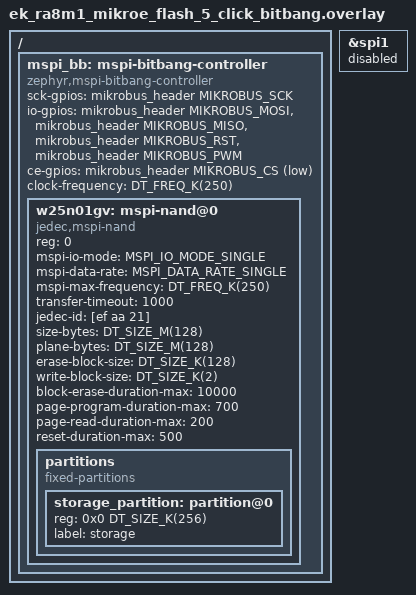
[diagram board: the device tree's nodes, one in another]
/*
 * Copyright The Zephyr Project Contributors
 *
 * SPDX-License-Identifier: Apache-2.0
 */

#include <zephyr/dt-bindings/gpio/mikro-bus.h>

/*
 * MikroE Flash 5 Click (Winbond W25N01GV) on the mikroBUS socket through the
 * bitbang MSPI controller. The socket SPI shares the CS, SCK, MISO and MOSI
 * pins.
 */

&spi1 {
	status = "disabled";
};

/delete-node/ &storage_partition;

/ {
	mspi_bb: mspi-bitbang-controller {
		compatible = "zephyr,mspi-bitbang-controller";
		#address-cells = <1>;
		#size-cells = <0>;
		sck-gpios = <&mikrobus_header MIKROBUS_SCK GPIO_ACTIVE_HIGH>;
		/*
		 * IO0 is the mikroBUS MOSI line (DI), IO1 the MISO line (DO), IO2 the
		 * RST line (/WP) and IO3 the PWM line (/HOLD). The click pulls /WP and
		 * /HOLD up.
		 */
		io-gpios = <&mikrobus_header MIKROBUS_MOSI GPIO_ACTIVE_HIGH>,
			   <&mikrobus_header MIKROBUS_MISO GPIO_ACTIVE_HIGH>,
			   <&mikrobus_header MIKROBUS_RST GPIO_ACTIVE_HIGH>,
			   <&mikrobus_header MIKROBUS_PWM GPIO_ACTIVE_HIGH>;
		ce-gpios = <&mikrobus_header MIKROBUS_CS GPIO_ACTIVE_LOW>;
		clock-frequency = <DT_FREQ_K(250)>;
		status = "okay";

		w25n01gv: mspi-nand@0 {
			compatible = "jedec,mspi-nand";
			reg = <0>;

			mspi-io-mode = "MSPI_IO_MODE_SINGLE";
			mspi-data-rate = "MSPI_DATA_RATE_SINGLE";
			mspi-max-frequency = <DT_FREQ_K(250)>;

			/* A page transfer on the bitbang bus exceeds the default */
			transfer-timeout = <1000>;

			/* w25n01gv parameters */
			jedec-id = [ef aa 21];
			size-bytes = <DT_SIZE_M(128)>;
			plane-bytes = <DT_SIZE_M(128)>;
			erase-block-size = <DT_SIZE_K(128)>;
			write-block-size = <DT_SIZE_K(2)>;
			block-erase-duration-max = <10000>;
			page-program-duration-max = <700>;
			page-read-duration-max = <200>;
			reset-duration-max = <500>;
			status = "okay";

			partitions {
				compatible = "fixed-partitions";
				#address-cells = <1>;
				#size-cells = <1>;

				storage_partition: partition@0 {
					reg = <0x0 DT_SIZE_K(256)>;
					label = "storage";
				};
			};
		};
	};
};
